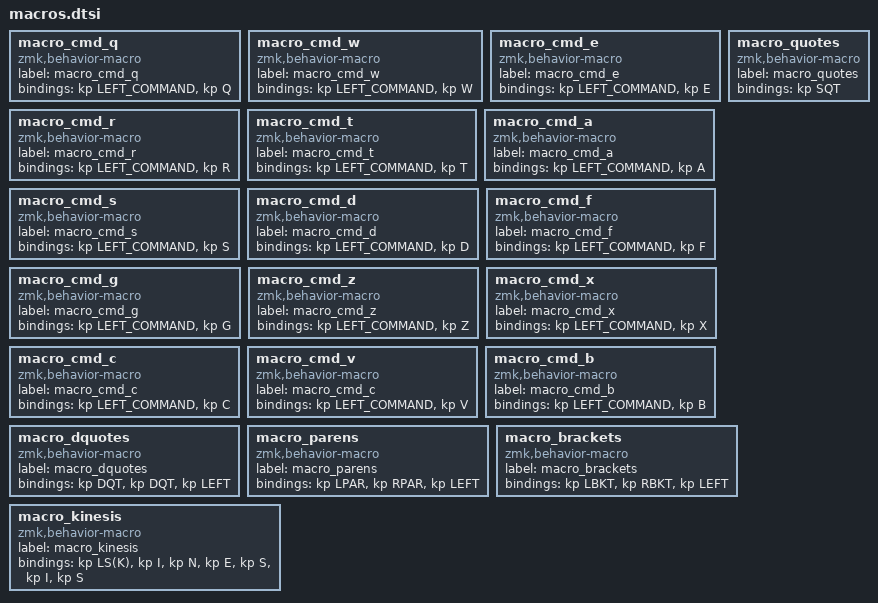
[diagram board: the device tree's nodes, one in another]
macro_cmd_q: macro_cmd_q{
compatible = "zmk,behavior-macro";
label = "macro_cmd_q";
#binding-cells = <0>;
bindings = <&kp LEFT_COMMAND>, <&kp Q>;
};
macro_cmd_w: macro_cmd_w{
compatible = "zmk,behavior-macro";
label = "macro_cmd_w";
#binding-cells = <0>;
bindings = <&kp LEFT_COMMAND>, <&kp W>;
};
macro_cmd_e: macro_cmd_e{
compatible = "zmk,behavior-macro";
label = "macro_cmd_e";
#binding-cells = <0>;
bindings = <&kp LEFT_COMMAND>, <&kp E>;
};
macro_cmd_r: macro_cmd_r{
compatible = "zmk,behavior-macro";
label = "macro_cmd_r";
#binding-cells = <0>;
bindings = <&kp LEFT_COMMAND>, <&kp R>;
};
macro_cmd_t: macro_cmd_t{
compatible = "zmk,behavior-macro";
label = "macro_cmd_t";
#binding-cells = <0>;
bindings = <&kp LEFT_COMMAND>, <&kp T>;
};
macro_cmd_a: macro_cmd_a{
compatible = "zmk,behavior-macro";
label = "macro_cmd_a";
#binding-cells = <0>;
bindings = <&kp LEFT_COMMAND>, <&kp A>;
};
macro_cmd_s: macro_cmd_s{
compatible = "zmk,behavior-macro";
label = "macro_cmd_s";
#binding-cells = <0>;
bindings = <&kp LEFT_COMMAND>, <&kp S>;
};
macro_cmd_d: macro_cmd_d{
compatible = "zmk,behavior-macro";
label = "macro_cmd_d";
#binding-cells = <0>;
bindings = <&kp LEFT_COMMAND>, <&kp D>;
};
macro_cmd_f: macro_cmd_f{
compatible = "zmk,behavior-macro";
label = "macro_cmd_f";
#binding-cells = <0>;
bindings = <&kp LEFT_COMMAND>, <&kp F>;
};
macro_cmd_g: macro_cmd_g{
compatible = "zmk,behavior-macro";
label = "macro_cmd_g";
#binding-cells = <0>;
bindings = <&kp LEFT_COMMAND>, <&kp G>;
};
macro_cmd_z: macro_cmd_z{
compatible = "zmk,behavior-macro";
label = "macro_cmd_z";
#binding-cells = <0>;
bindings = <&kp LEFT_COMMAND>, <&kp Z>;
};
macro_cmd_x: macro_cmd_x{
compatible = "zmk,behavior-macro";
label = "macro_cmd_x";
#binding-cells = <0>;
bindings = <&kp LEFT_COMMAND>, <&kp X>;
};
macro_cmd_c: macro_cmd_c{
compatible = "zmk,behavior-macro";
label = "macro_cmd_c";
#binding-cells = <0>;
bindings = <&kp LEFT_COMMAND>, <&kp C>;
};
macro_cmd_v: macro_cmd_v{
compatible = "zmk,behavior-macro";
label = "macro_cmd_c";
#binding-cells = <0>;
bindings = <&kp LEFT_COMMAND>, <&kp V>;
};
macro_cmd_b: macro_cmd_b{
compatible = "zmk,behavior-macro";
label = "macro_cmd_b";
#binding-cells = <0>;
bindings = <&kp LEFT_COMMAND>, <&kp B>;
};
macro_quotes: macro_quotes{
compatible = "zmk,behavior-macro";
label = "macro_quotes";
#binding-cells = <0>;
bindings = <&kp SQT>;
};
macro_dquotes: macro_dquotes{
compatible = "zmk,behavior-macro";
label = "macro_dquotes";
#binding-cells = <0>;
bindings = <&kp DQT>, <&kp DQT>, <&kp LEFT>;
};
macro_parens: macro_parens{
compatible = "zmk,behavior-macro";
label = "macro_parens";
#binding-cells = <0>;
bindings = <&kp LPAR>, <&kp RPAR>, <&kp LEFT>;
};
macro_brackets: macro_brackets{
compatible = "zmk,behavior-macro";
label = "macro_brackets";
#binding-cells = <0>;
bindings = <&kp LBKT>, <&kp RBKT>, <&kp LEFT>;
};
macro_kinesis: macro_kinesis{
compatible = "zmk,behavior-macro";
label = "macro_kinesis";
#binding-cells = <0>;
bindings = <&kp LS(K)>, <&kp I>, <&kp N>, <&kp E>, <&kp S>, <&kp I>, <&kp S>;
};
